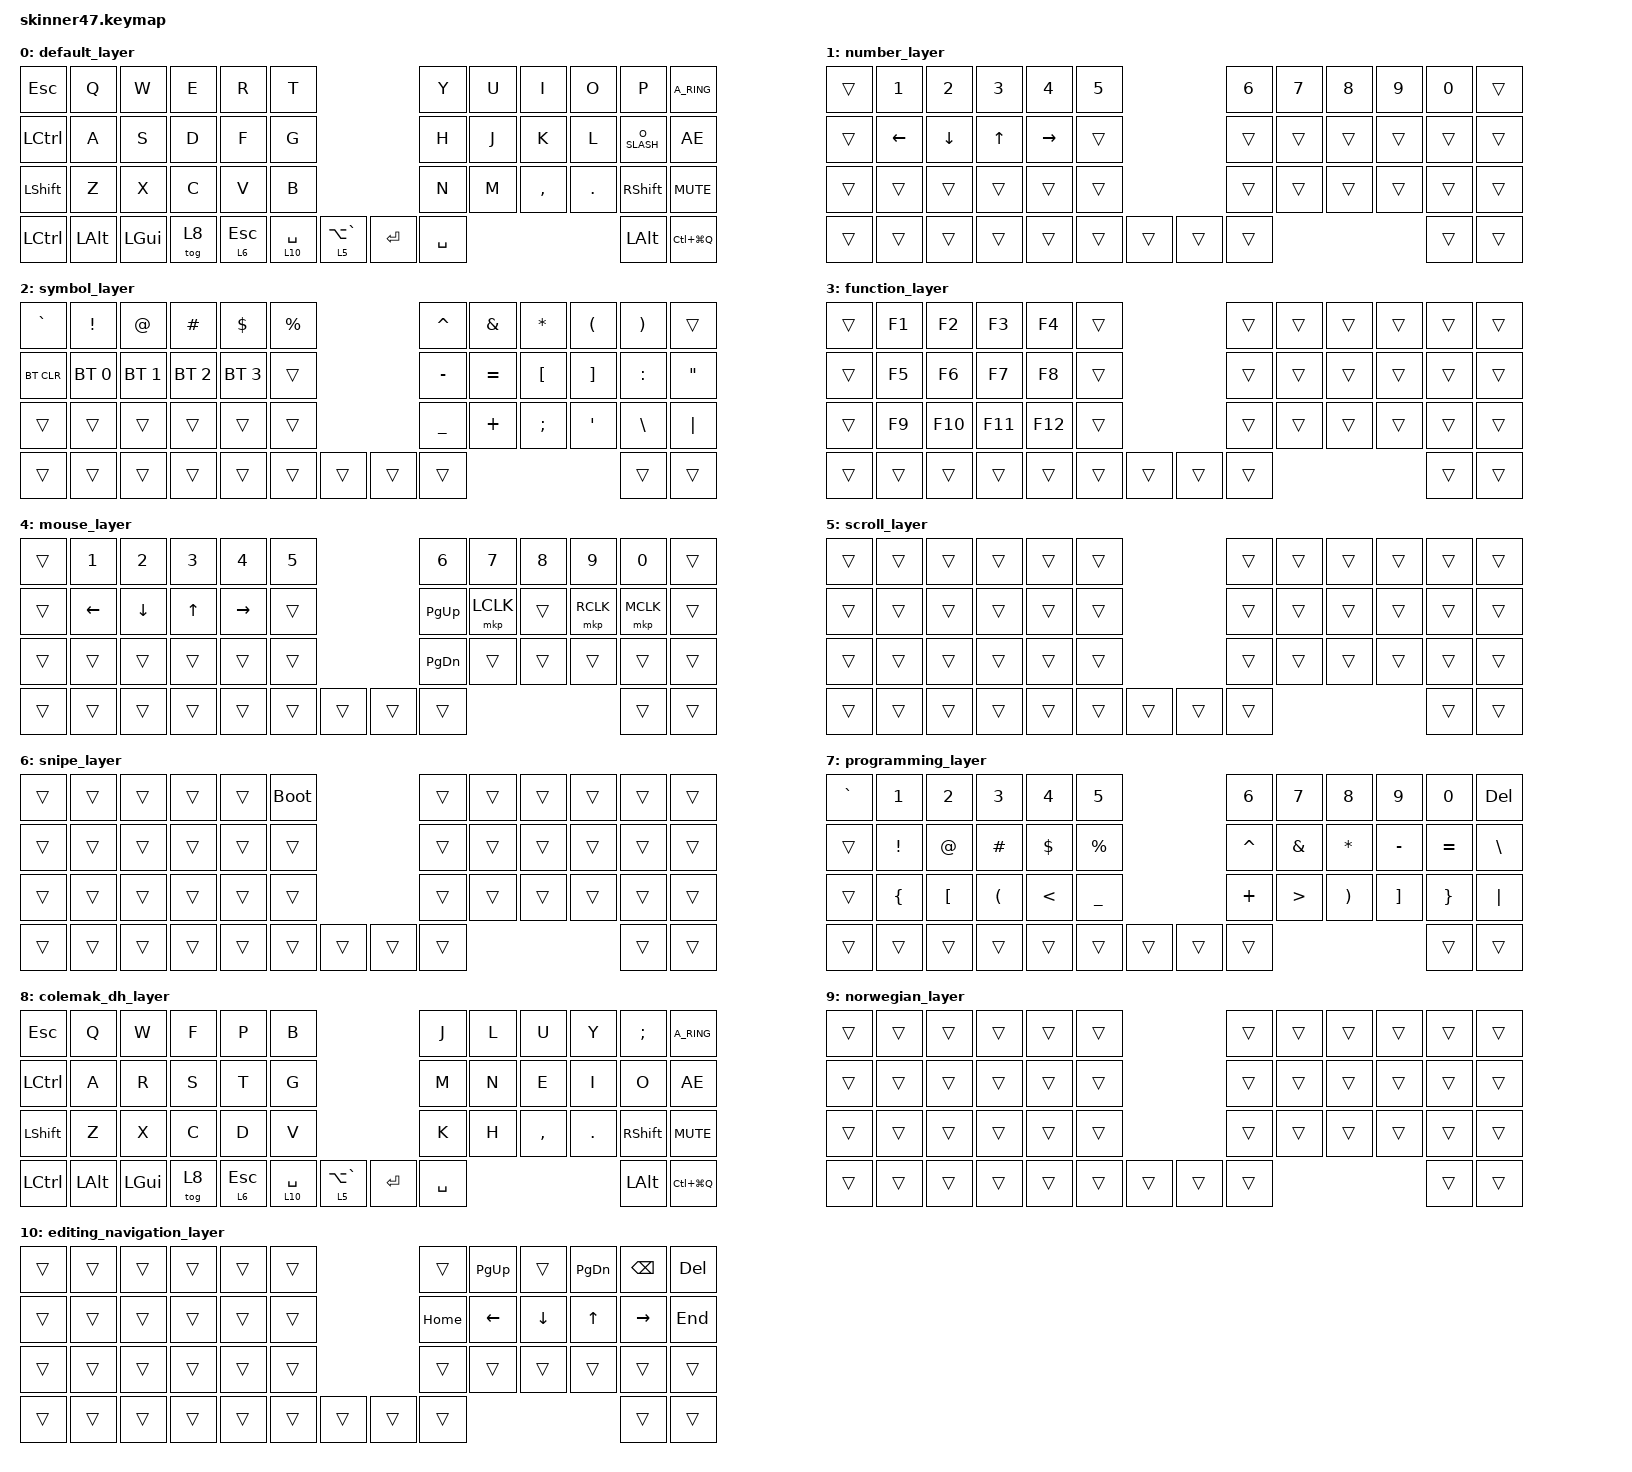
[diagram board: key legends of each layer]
#include <behaviors.dtsi>
#include <dt-bindings/zmk/bt.h>
#include <dt-bindings/zmk/keys.h>
#include <dt-bindings/zmk/pointing.h>

/ {
    keymap {
        compatible = "zmk,keymap";

        default_layer {
            bindings =
&kp ESC    &kp Q      &kp W      &kp E       &kp R         &kp T                                    &kp Y       &kp U       &kp I      &kp O       &kp P            &kp A_RING
&kp LCTRL  &kp A      &kp S      &kp D       &kp F         &kp G                                    &kp H       &kp J       &kp K      &kp L       &kp O_SLASH      &kp AE
&kp LSHFT  &kp Z      &kp X      &kp C       &kp V         &kp B                                    &kp N       &kp M       &kp COMMA  &kp DOT     &kp RSHFT        &kp C_MUTE
&kp LCTRL  &kp LALT   &kp LGUI   &tog 8      &lt 6 ESCAPE  &lt 10 SPACE  &lt 5 LA(GRAVE)  &kp ENTER  &kp SPACE                                  &kp LALT         &kp LC(LG(Q))
            >;
        };

        number_layer {
            bindings =
&trans  &kp N1    &kp N2    &kp N3        &kp N4     &kp N5                  &kp N6  &kp N7  &kp N8  &kp N9  &kp N0  &trans
&trans  &kp LEFT  &kp DOWN  &kp UP_ARROW  &kp RIGHT  &trans                  &trans  &trans  &trans  &trans  &trans  &trans
&trans  &trans    &trans    &trans        &trans     &trans                  &trans  &trans  &trans  &trans  &trans  &trans
&trans  &trans    &trans    &trans        &trans     &trans  &trans  &trans  &trans                          &trans  &trans
            >;
        };

        symbol_layer {
            bindings =
&kp GRAVE   &kp EXCLAMATION  &kp AT_SIGN   &kp HASH      &kp DOLLAR    &kp PERCENT                  &kp CARET       &kp AMPERSAND  &kp ASTERISK      &kp LEFT_PARENTHESIS  &kp RIGHT_PARENTHESIS  &trans
&bt BT_CLR  &bt BT_SEL 0     &bt BT_SEL 1  &bt BT_SEL 2  &bt BT_SEL 3  &trans                       &kp MINUS       &kp EQUAL      &kp LEFT_BRACKET  &kp RIGHT_BRACKET     &kp COLON              &kp DOUBLE_QUOTES
&trans      &trans           &trans        &trans        &trans        &trans                       &kp UNDERSCORE  &kp PLUS       &kp SEMI          &kp APOS              &kp BACKSLASH          &kp PIPE
&trans      &trans           &trans        &trans        &trans        &trans       &trans  &trans  &trans                                                                 &trans                 &trans
            >;
        };

        function_layer {
            bindings =
&trans  &kp F1  &kp F2   &kp F3   &kp F4   &trans                  &trans  &trans  &trans  &trans  &trans  &trans
&trans  &kp F5  &kp F6   &kp F7   &kp F8   &trans                  &trans  &trans  &trans  &trans  &trans  &trans
&trans  &kp F9  &kp F10  &kp F11  &kp F12  &trans                  &trans  &trans  &trans  &trans  &trans  &trans
&trans  &trans  &trans   &trans   &trans   &trans  &trans  &trans  &trans                          &trans  &trans
            >;
        };

        mouse_layer {
            bindings =
&trans  &kp N1    &kp N2    &kp N3  &kp N4     &kp N5                  &kp N6         &kp N7     &kp N8  &kp N9     &kp N0     &trans
&trans  &kp LEFT  &kp DOWN  &kp UP  &kp RIGHT  &trans                  &kp PAGE_UP    &mkp LCLK  &trans  &mkp RCLK  &mkp MCLK  &trans
&trans  &trans    &trans    &trans  &trans     &trans                  &kp PAGE_DOWN  &trans     &trans  &trans     &trans     &trans
&trans  &trans    &trans    &trans  &trans     &trans  &trans  &trans  &trans                                       &trans     &trans
            >;
        };

        scroll_layer {
            bindings =
&trans  &trans  &trans  &trans  &trans  &trans                  &trans  &trans  &trans  &trans  &trans  &trans
&trans  &trans  &trans  &trans  &trans  &trans                  &trans  &trans  &trans  &trans  &trans  &trans
&trans  &trans  &trans  &trans  &trans  &trans                  &trans  &trans  &trans  &trans  &trans  &trans
&trans  &trans  &trans  &trans  &trans  &trans  &trans  &trans  &trans                          &trans  &trans
            >;
        };

        snipe_layer {
            bindings =
&trans  &trans  &trans  &trans  &trans  &bootloader                  &trans  &trans  &trans  &trans  &trans  &trans
&trans  &trans  &trans  &trans  &trans  &trans                       &trans  &trans  &trans  &trans  &trans  &trans
&trans  &trans  &trans  &trans  &trans  &trans                       &trans  &trans  &trans  &trans  &trans  &trans
&trans  &trans  &trans  &trans  &trans  &trans       &trans  &trans  &trans                          &trans  &trans
            >;
        };

        programming_layer {
            bindings =
&kp GRAVE  &kp N1    &kp N2    &kp N3    &kp N4   &kp N5                      &kp N6     &kp N7    &kp N8        &kp N9    &kp N0     &kp DELETE
&trans     &kp EXCL  &kp AT    &kp HASH  &kp DLLR &kp PRCNT                   &kp CARET  &kp AMPS  &kp ASTERISK  &kp MINUS &kp EQUAL  &kp BACKSLASH
&trans     &kp LBRC  &kp LBKT  &kp LPAR  &kp LT   &kp UNDER                   &kp PLUS   &kp GT    &kp RPAR      &kp RBKT  &kp RBRC   &kp PIPE
&trans     &trans    &trans    &trans    &trans   &trans     &trans   &trans  &trans                                       &trans     &trans
            >;
        };

        colemak_dh_layer {
            bindings =
&kp ESC    &kp Q      &kp W      &kp F       &kp P         &kp B                                    &kp J       &kp L       &kp U      &kp Y       &kp SEMI         &kp A_RING
&kp LCTRL  &kp A      &kp R      &kp S       &kp T         &kp G                                    &kp M       &kp N       &kp E      &kp I       &kp O            &kp AE
&kp LSHFT  &kp Z      &kp X      &kp C       &kp D         &kp V                                    &kp K       &kp H       &kp COMMA  &kp DOT     &kp RSHFT        &kp C_MUTE
&kp LCTRL  &kp LALT   &kp LGUI   &tog 8      &lt 6 ESCAPE  &lt 10 SPACE  &lt 5 LA(GRAVE)  &kp ENTER  &kp SPACE                                  &kp LALT         &kp LC(LG(Q))
            >;
        };

        norwegian_layer {
            bindings =
&trans  &trans  &trans  &trans  &trans  &trans                  &trans  &trans  &trans  &trans  &trans  &trans
&trans  &trans  &trans  &trans  &trans  &trans                  &trans  &trans  &trans  &trans  &trans  &trans
&trans  &trans  &trans  &trans  &trans  &trans                  &trans  &trans  &trans  &trans  &trans  &trans
&trans  &trans  &trans  &trans  &trans  &trans  &trans  &trans  &trans                          &trans  &trans
            >;
        };

        editing_navigation_layer {
            bindings =
&trans  &trans  &trans      &trans  &trans      &trans                  &trans     &kp PG_UP  &trans     &kp PG_DN  &kp BSPC   &kp DEL
&trans  &trans  &trans      &trans  &trans      &trans                  &kp HOME   &kp LEFT   &kp DOWN   &kp UP     &kp RIGHT  &kp END
&trans  &trans  &trans      &trans  &trans      &trans                  &trans     &trans     &trans     &trans     &trans     &trans
&trans  &trans  &trans      &trans  &trans      &trans  &trans  &trans  &trans                                       &trans     &trans
            >;
        };
    };
};
